# MCU_CTRL_MMR0_CFG0 register map
Vendor: Texas Instruments
Registers are 32-bit, read-write, reset 0x0 unless marked. A register's access mark holds for its fields unless they carry their own. Offsets are as the file gives them; [hi:lo] are bit positions; {n}, {i} and the like mark numbered series.

## MCU_CTRL_MMR0_CFG0 (part 2 of 2)
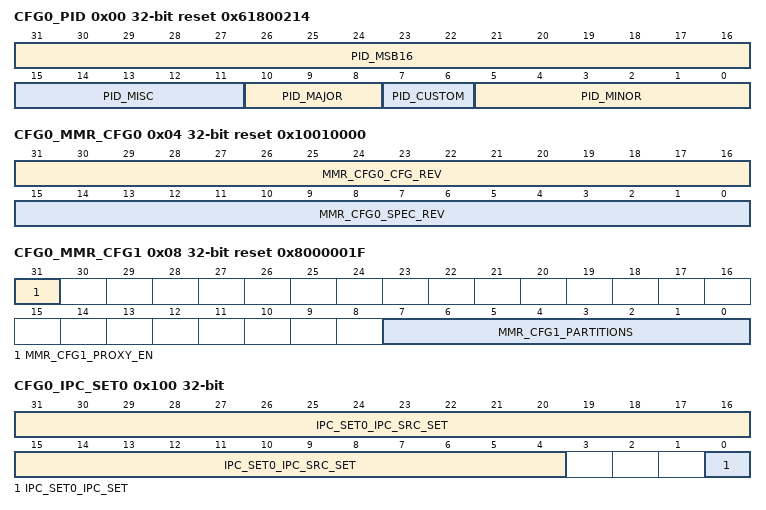
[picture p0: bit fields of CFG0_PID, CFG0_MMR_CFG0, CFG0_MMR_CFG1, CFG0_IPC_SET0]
0x00 CFG0_PID ro reset 0x61800214
  [31:16] PID_MSB16, [15:11] PID_MISC, [10:8] PID_MAJOR, [7:6] PID_CUSTOM, [5:0] PID_MINOR
0x04 CFG0_MMR_CFG0 ro reset 0x10010000
  [31:16] MMR_CFG0_CFG_REV — Major configuration release
  [15:0] MMR_CFG0_SPEC_REV — Minor spec-only revision. Doesn't change with RTL release so RTL will always read as 16'h0000
0x08 CFG0_MMR_CFG1 ro reset 0x8000001F
  [31] MMR_CFG1_PROXY_EN — Proxy addressing enabled
  [7:0] MMR_CFG1_PARTITIONS — Indicates present partitions
0x100 CFG0_IPC_SET0 access not given
  [31:4] IPC_SET0_IPC_SRC_SET — Read returns current value Write: 0 - No effect 1 - Sets both SRC_SETx and the SRC_CLRx bit in the corresponding IPC_CLR register (access R/W1TS)
  [0] IPC_SET0_IPC_SET — Read returns 0 Write: 0 - No effect 1 - Sets both the IPC_SET and the IPC_CLR bit in the corresponding IPC_CLR register (access R/W1TS)
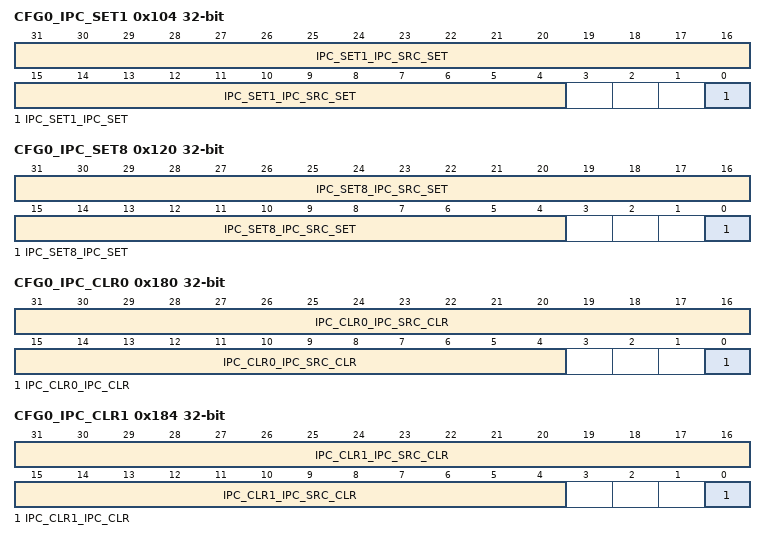
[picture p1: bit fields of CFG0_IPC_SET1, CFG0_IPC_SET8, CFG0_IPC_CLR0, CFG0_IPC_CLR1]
0x104 CFG0_IPC_SET1 access not given
  [31:4] IPC_SET1_IPC_SRC_SET — Read returns current value Write: 0 - No effect 1 - Sets both SRC_SETx and the SRC_CLRx bit in the corresponding IPC_CLR register (access R/W1TS)
  [0] IPC_SET1_IPC_SET — Read returns 0 Write: 0 - No effect 1 - Sets both the IPC_SET and the IPC_CLR bit in the corresponding IPC_CLR register (access R/W1TS)
0x120 CFG0_IPC_SET8 access not given
  [31:4] IPC_SET8_IPC_SRC_SET — Read returns current value Write: 0 - No effect 1 - Sets both SRC_SETx and the SRC_CLRx bit in the corresponding IPC_CLR register (access R/W1TS)
  [0] IPC_SET8_IPC_SET — Read returns 0 Write: 0 - No effect 1 - Sets both the IPC_SET and the IPC_CLR bit in the corresponding IPC_CLR register (access R/W1TS)
0x180 CFG0_IPC_CLR0 access not given
  [31:4] IPC_CLR0_IPC_SRC_CLR — Read returns current value Write: 0 - No effect 1 - Clears both SRC_CLRx and the SRC_SETx bit in the corresponding IPC_GEN register (access R/W1TC)
  [0] IPC_CLR0_IPC_CLR — Read returns current value Write: 0 - No effect 1 - Clears both IPC_CLR and the IPC_SET bit in the corresponding IPC_SET register (access R/W1TC)
0x184 CFG0_IPC_CLR1 access not given
  [31:4] IPC_CLR1_IPC_SRC_CLR — Read returns current value Write: 0 - No effect 1 - Clears both SRC_CLRx and the SRC_SETx bit in the corresponding IPC_GEN register (access R/W1TC)
  [0] IPC_CLR1_IPC_CLR — Read returns current value Write: 0 - No effect 1 - Clears both IPC_CLR and the IPC_SET bit in the corresponding IPC_SET register (access R/W1TC)
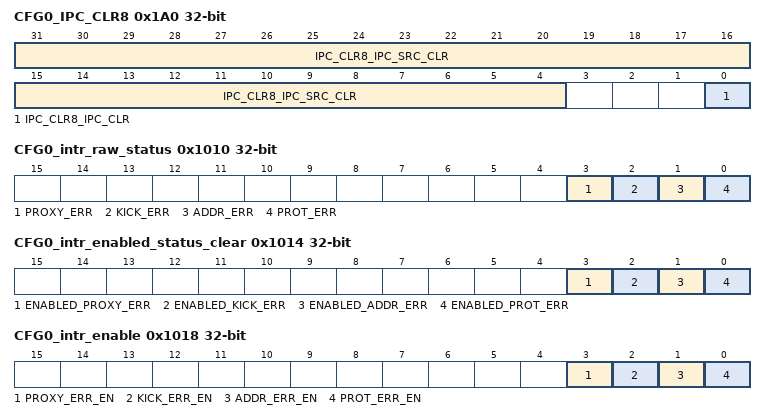
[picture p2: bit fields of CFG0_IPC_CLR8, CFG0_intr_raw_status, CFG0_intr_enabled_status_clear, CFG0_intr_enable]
0x1A0 CFG0_IPC_CLR8 access not given
  [31:4] IPC_CLR8_IPC_SRC_CLR — Read returns current value Write: 0 - No effect 1 - Clears both SRC_CLRx and the SRC_SETx bit in the corresponding IPC_GEN register (access R/W1TC)
  [0] IPC_CLR8_IPC_CLR — Read returns current value Write: 0 - No effect 1 - Clears both IPC_CLR and the IPC_SET bit in the corresponding IPC_SET register (access R/W1TC)
0x200 CFG0_MAC_ID0
  [31:0] MAC_ID0_MACID_LO — 32 lsbs of MAC address This bitfield may be written only once after each module reset .
0x204 CFG0_MAC_ID1
  [15:0] MAC_ID1_MACID_HI — 16 msbs of MAC address This bitfield may be written only once after each module reset .
0x208 CFG0_MAC_ID_COUNT ro
  [3:0] MAC_ID_COUNT_COUNT — Indicates the number of MAC addresses to be assigned
{0x1008+0x4000*i} CFG0_LOCK{i}_KICK0 (i=0..4)
  [31:0] LOCK{i}_KICK0 — - KICK0 component
{0x100C+0x4000*i} CFG0_LOCK{i}_KICK1 (i=0..4)
  [31:0] LOCK{i}_KICK1 — - KICK1 component
0x1010 CFG0_intr_raw_status access not given
  [3] PROXY_ERR — Proxy0 access violation error. Raw status is read. Write a 1 to set the status. Writing a 0 has no effect. (access R/W1TS)
  [2] KICK_ERR — Kick access violation error. Raw status is read. Write a 1 to set the status. Writing a 0 has no effect. (access R/W1TS)
  [1] ADDR_ERR — Addressing violation error. Raw status is read. Write a 1 to set the status. Writing a 0 has no effect. (access R/W1TS)
  [0] PROT_ERR — Protection violation error. Raw status is read. Write a 1 to set the status. Writing a 0 has no effect. (access R/W1TS)
0x1014 CFG0_intr_enabled_status_clear access not given
  [3] ENABLED_PROXY_ERR — Proxy0 access violation error. Enabled status is read. Write a 1 to clear the status. Writing a 0 has no effect. (access R/W1TC)
  [2] ENABLED_KICK_ERR — Kick access violation error. Enabled status is read. Write a 1 to clear the status. Writing a 0 has no effect. (access R/W1TC)
  [1] ENABLED_ADDR_ERR — Addressing violation error. Enabled status is read. Write a 1 to clear the status. Writing a 0 has no effect. (access R/W1TC)
  [0] ENABLED_PROT_ERR — Protection violation error. Enabled status is read. Write a 1 to clear the status. Writing a 0 has no effect. (access R/W1TC)
0x1018 CFG0_intr_enable access not given
  [3] PROXY_ERR_EN — Proxy0 access violation error enable. Write a 1 to set the enable. Writing a 0 has no effect. (access R/W1TS)
  [2] KICK_ERR_EN — Kick access violation error enable. Write a 1 to set the enable. Writing a 0 has no effect. (access R/W1TS)
  [1] ADDR_ERR_EN — Addressing violation error enable. Write a 1 to set the enable. Writing a 0 has no effect. (access R/W1TS)
  [0] PROT_ERR_EN — Protection violation error enable. Write a 1 to set the enable. Writing a 0 has no effect. (access R/W1TS)
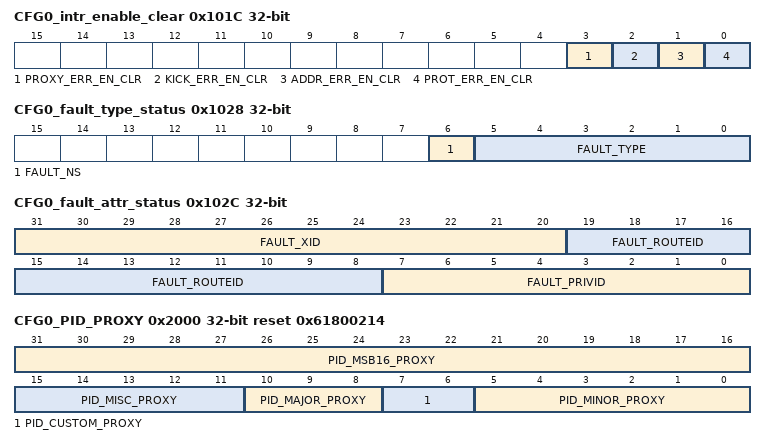
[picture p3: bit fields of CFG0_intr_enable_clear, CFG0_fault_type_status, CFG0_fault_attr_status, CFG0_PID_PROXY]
0x101C CFG0_intr_enable_clear access not given
  [3] PROXY_ERR_EN_CLR — Proxy0 access violation error enable clear. Write a 1 to clear the enable. Writing a 0 has no effect. (access R/W1TC)
  [2] KICK_ERR_EN_CLR — Kick access violation error enable clear. Write a 1 to clear the enable. Writing a 0 has no effect. (access R/W1TC)
  [1] ADDR_ERR_EN_CLR — Addressing violation error enable clear. Write a 1 to clear the enable. Writing a 0 has no effect. (access R/W1TC)
  [0] PROT_ERR_EN_CLR — Protection violation error enable clear. Write a 1 to clear the enable. Writing a 0 has no effect. (access R/W1TC)
0x1020 CFG0_eoi
  [7:0] EOI_VECTOR — EOI vector value. Write this with interrupt distribution value in the chip.
0x1024 CFG0_fault_address ro
  [31:0] FAULT_ADDR — Fault Address.
0x1028 CFG0_fault_type_status ro
  [6] FAULT_NS — Non-secure access.
  [5:0] FAULT_TYPE — Fault Type 10_0000 = Supervisor read fault - priv = 1 dir = 1 dtype != 1 01_0000 = Supervisor write fault - priv = 1 dir = 0 00_1000 = Supervisor execute fault - priv = 1 dir = 1 dtype = 1 00_0100 = User read fault - priv = 0 dir = 1 dtype = 1 00_0010 = User write fault - priv = 0 dir = 0 00_0001 = User execute fault - priv = 0 dir = 1 dtype = 1 00_0000 = No fault
0x102C CFG0_fault_attr_status ro
  [31:20] FAULT_XID — XID.
  [19:8] FAULT_ROUTEID — Route ID.
  [7:0] FAULT_PRIVID — Privilege ID.
0x1030 CFG0_fault_clear wo
  [0] FAULT_CLR — Fault clear. Writing a 1 clears the current fault. Writing a 0 has no effect.
{0x1100+4i} CFG0_CLAIMREG_P0_R{i}_READONLY ro (i=0..4)
  [31:0] CLAIMREG_P0_R{i}_READONLY — Claim bits for Partition 0
0x2000 CFG0_PID_PROXY ro reset 0x61800214
  [31:16] PID_MSB16_PROXY, [15:11] PID_MISC_PROXY, [10:8] PID_MAJOR_PROXY, [7:6] PID_CUSTOM_PROXY, [5:0] PID_MINOR_PROXY
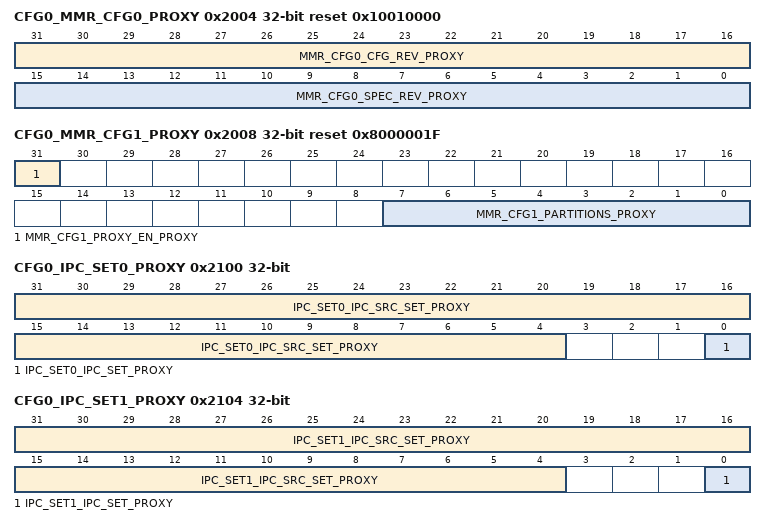
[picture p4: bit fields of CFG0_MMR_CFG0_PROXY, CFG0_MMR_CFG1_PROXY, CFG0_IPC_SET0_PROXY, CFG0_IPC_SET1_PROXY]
0x2004 CFG0_MMR_CFG0_PROXY ro reset 0x10010000
  [31:16] MMR_CFG0_CFG_REV_PROXY — Major configuration release
  [15:0] MMR_CFG0_SPEC_REV_PROXY — Minor spec-only revision. Doesn't change with RTL release so RTL will always read as 16'h0000
0x2008 CFG0_MMR_CFG1_PROXY ro reset 0x8000001F
  [31] MMR_CFG1_PROXY_EN_PROXY — Proxy addressing enabled
  [7:0] MMR_CFG1_PARTITIONS_PROXY — Indicates present partitions
0x2100 CFG0_IPC_SET0_PROXY access not given
  [31:4] IPC_SET0_IPC_SRC_SET_PROXY — Read returns current value Write: 0 - No effect 1 - Sets both SRC_SETx and the SRC_CLRx bit in the corresponding IPC_CLR register (access R/W1TS)
  [0] IPC_SET0_IPC_SET_PROXY — Read returns 0 Write: 0 - No effect 1 - Sets both the IPC_SET and the IPC_CLR bit in the corresponding IPC_CLR register (access R/W1TS)
0x2104 CFG0_IPC_SET1_PROXY access not given
  [31:4] IPC_SET1_IPC_SRC_SET_PROXY — Read returns current value Write: 0 - No effect 1 - Sets both SRC_SETx and the SRC_CLRx bit in the corresponding IPC_CLR register (access R/W1TS)
  [0] IPC_SET1_IPC_SET_PROXY — Read returns 0 Write: 0 - No effect 1 - Sets both the IPC_SET and the IPC_CLR bit in the corresponding IPC_CLR register (access R/W1TS)
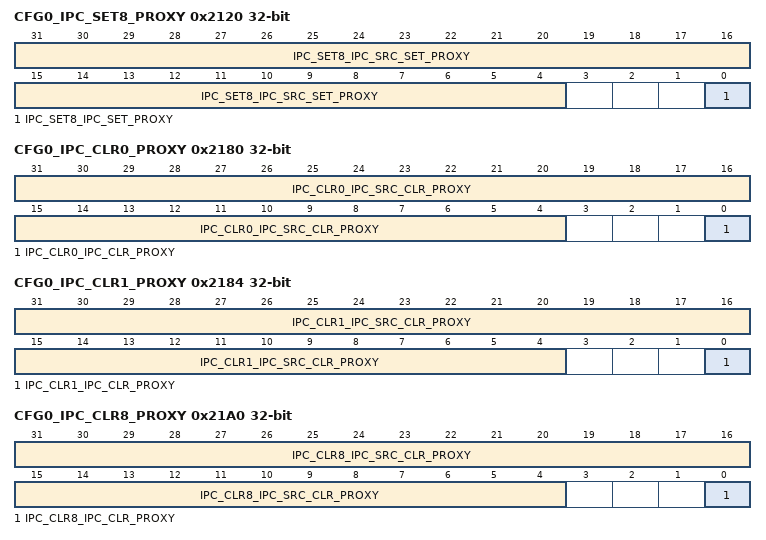
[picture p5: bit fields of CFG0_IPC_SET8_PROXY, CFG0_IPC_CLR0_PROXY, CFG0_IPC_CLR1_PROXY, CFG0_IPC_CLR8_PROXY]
0x2120 CFG0_IPC_SET8_PROXY access not given
  [31:4] IPC_SET8_IPC_SRC_SET_PROXY — Read returns current value Write: 0 - No effect 1 - Sets both SRC_SETx and the SRC_CLRx bit in the corresponding IPC_CLR register (access R/W1TS)
  [0] IPC_SET8_IPC_SET_PROXY — Read returns 0 Write: 0 - No effect 1 - Sets both the IPC_SET and the IPC_CLR bit in the corresponding IPC_CLR register (access R/W1TS)
0x2180 CFG0_IPC_CLR0_PROXY access not given
  [31:4] IPC_CLR0_IPC_SRC_CLR_PROXY — Read returns current value Write: 0 - No effect 1 - Clears both SRC_CLRx and the SRC_SETx bit in the corresponding IPC_GEN register (access R/W1TC)
  [0] IPC_CLR0_IPC_CLR_PROXY — Read returns current value Write: 0 - No effect 1 - Clears both IPC_CLR and the IPC_SET bit in the corresponding IPC_SET register (access R/W1TC)
0x2184 CFG0_IPC_CLR1_PROXY access not given
  [31:4] IPC_CLR1_IPC_SRC_CLR_PROXY — Read returns current value Write: 0 - No effect 1 - Clears both SRC_CLRx and the SRC_SETx bit in the corresponding IPC_GEN register (access R/W1TC)
  [0] IPC_CLR1_IPC_CLR_PROXY — Read returns current value Write: 0 - No effect 1 - Clears both IPC_CLR and the IPC_SET bit in the corresponding IPC_SET register (access R/W1TC)
0x21A0 CFG0_IPC_CLR8_PROXY access not given
  [31:4] IPC_CLR8_IPC_SRC_CLR_PROXY — Read returns current value Write: 0 - No effect 1 - Clears both SRC_CLRx and the SRC_SETx bit in the corresponding IPC_GEN register (access R/W1TC)
  [0] IPC_CLR8_IPC_CLR_PROXY — Read returns current value Write: 0 - No effect 1 - Clears both IPC_CLR and the IPC_SET bit in the corresponding IPC_SET register (access R/W1TC)
0x2200 CFG0_MAC_ID0_PROXY
  [31:0] MAC_ID0_MACID_LO_PROXY — 32 lsbs of MAC address This bitfield may be written only once after each module reset .
0x2204 CFG0_MAC_ID1_PROXY
  [15:0] MAC_ID1_MACID_HI_PROXY — 16 msbs of MAC address This bitfield may be written only once after each module reset .
0x2208 CFG0_MAC_ID_COUNT_PROXY ro
  [3:0] MAC_ID_COUNT_COUNT_PROXY — Indicates the number of MAC addresses to be assigned
{0x3008+0x4000*i} CFG0_LOCK{i}_KICK0_PROXY (i=0..4)
  [31:0] LOCK{i}_KICK0_PROXY — - KICK0 component
{0x300C+0x4000*i} CFG0_LOCK{i}_KICK1_PROXY (i=0..4)
  [31:0] LOCK{i}_KICK1_PROXY — - KICK1 component
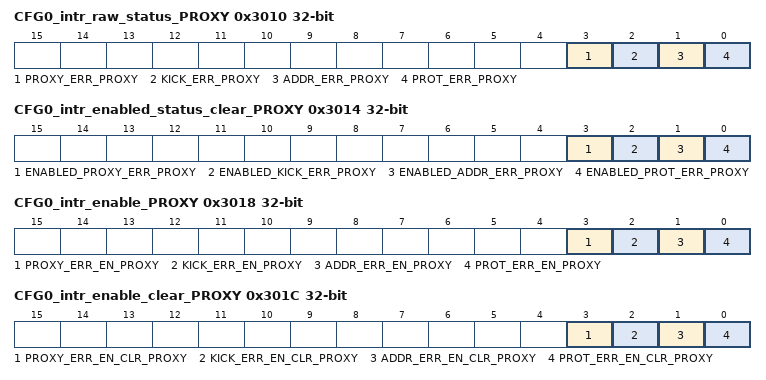
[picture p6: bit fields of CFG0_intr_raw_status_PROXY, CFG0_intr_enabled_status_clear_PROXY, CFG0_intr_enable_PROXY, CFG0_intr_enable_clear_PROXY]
0x3010 CFG0_intr_raw_status_PROXY access not given
  [3] PROXY_ERR_PROXY — Proxy0 access violation error. Raw status is read. Write a 1 to set the status. Writing a 0 has no effect. (access R/W1TS)
  [2] KICK_ERR_PROXY — Kick access violation error. Raw status is read. Write a 1 to set the status. Writing a 0 has no effect. (access R/W1TS)
  [1] ADDR_ERR_PROXY — Addressing violation error. Raw status is read. Write a 1 to set the status. Writing a 0 has no effect. (access R/W1TS)
  [0] PROT_ERR_PROXY — Protection violation error. Raw status is read. Write a 1 to set the status. Writing a 0 has no effect. (access R/W1TS)
0x3014 CFG0_intr_enabled_status_clear_PROXY access not given
  [3] ENABLED_PROXY_ERR_PROXY — Proxy0 access violation error. Enabled status is read. Write a 1 to clear the status. Writing a 0 has no effect. (access R/W1TC)
  [2] ENABLED_KICK_ERR_PROXY — Kick access violation error. Enabled status is read. Write a 1 to clear the status. Writing a 0 has no effect. (access R/W1TC)
  [1] ENABLED_ADDR_ERR_PROXY — Addressing violation error. Enabled status is read. Write a 1 to clear the status. Writing a 0 has no effect. (access R/W1TC)
  [0] ENABLED_PROT_ERR_PROXY — Protection violation error. Enabled status is read. Write a 1 to clear the status. Writing a 0 has no effect. (access R/W1TC)
0x3018 CFG0_intr_enable_PROXY access not given
  [3] PROXY_ERR_EN_PROXY — Proxy0 access violation error enable. Write a 1 to set the enable. Writing a 0 has no effect. (access R/W1TS)
  [2] KICK_ERR_EN_PROXY — Kick access violation error enable. Write a 1 to set the enable. Writing a 0 has no effect. (access R/W1TS)
  [1] ADDR_ERR_EN_PROXY — Addressing violation error enable. Write a 1 to set the enable. Writing a 0 has no effect. (access R/W1TS)
  [0] PROT_ERR_EN_PROXY — Protection violation error enable. Write a 1 to set the enable. Writing a 0 has no effect. (access R/W1TS)
0x301C CFG0_intr_enable_clear_PROXY access not given
  [3] PROXY_ERR_EN_CLR_PROXY — Proxy0 access violation error enable clear. Write a 1 to clear the enable. Writing a 0 has no effect. (access R/W1TC)
  [2] KICK_ERR_EN_CLR_PROXY — Kick access violation error enable clear. Write a 1 to clear the enable. Writing a 0 has no effect. (access R/W1TC)
  [1] ADDR_ERR_EN_CLR_PROXY — Addressing violation error enable clear. Write a 1 to clear the enable. Writing a 0 has no effect. (access R/W1TC)
  [0] PROT_ERR_EN_CLR_PROXY — Protection violation error enable clear. Write a 1 to clear the enable. Writing a 0 has no effect. (access R/W1TC)
0x3020 CFG0_eoi_PROXY
  [7:0] EOI_VECTOR_PROXY — EOI vector value. Write this with interrupt distribution value in the chip.
0x3024 CFG0_fault_address_PROXY ro
  [31:0] FAULT_ADDR_PROXY — Fault Address.
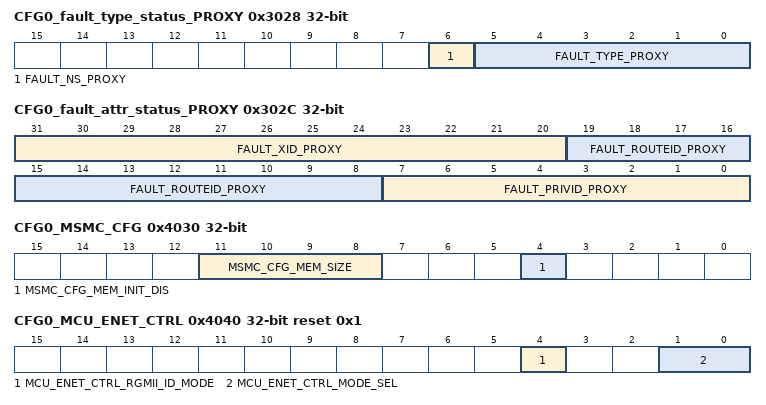
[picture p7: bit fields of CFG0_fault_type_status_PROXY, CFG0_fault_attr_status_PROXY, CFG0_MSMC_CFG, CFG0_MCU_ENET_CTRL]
0x3028 CFG0_fault_type_status_PROXY ro
  [6] FAULT_NS_PROXY — Non-secure access.
  [5:0] FAULT_TYPE_PROXY — Fault Type 10_0000 = Supervisor read fault - priv = 1 dir = 1 dtype != 1 01_0000 = Supervisor write fault - priv = 1 dir = 0 00_1000 = Supervisor execute fault - priv = 1 dir = 1 dtype = 1 00_0100 = User read fault - priv = 0 dir = 1 dtype = 1 00_0010 = User write fault - priv = 0 dir = 0 00_0001 = User execute fault - priv = 0 dir = 1 dtype = 1 00_0000 = No fault
0x302C CFG0_fault_attr_status_PROXY ro
  [31:20] FAULT_XID_PROXY — XID.
  [19:8] FAULT_ROUTEID_PROXY — Route ID.
  [7:0] FAULT_PRIVID_PROXY — Privilege ID.
0x3030 CFG0_fault_clear_PROXY wo
  [0] FAULT_CLR_PROXY — Fault clear. Writing a 1 clears the current fault. Writing a 0 has no effect.
{0x3100+4i} CFG0_CLAIMREG_P0_R{i} (i=0..4)
  [31:0] CLAIMREG_P0_R{i} — Claim bits for Partition 0
0x4030 CFG0_MSMC_CFG access per field
  [11:8] MSMC_CFG_MEM_SIZE ro — Indicates the size of MSMC shared SRAM/Cache Field values (others are reserved): undefined - undefined undefined - undefined undefined - undefined undefined - undefined undefined - undefined undefined - undefined undefined - undefined undefined - undefined undefined - undefined undefined - undefined undefined - undefined undefined - undefined undefined - undefined undefined - undefined 4'b0000 - 0.5 MB 4'b0001 - 1.75 MB 4'b0010 - 3.0 MB 4'b0011 - 4,25 MB 4'b0100 - 5.5 MB 4'b0101 - 6.75 MB 4'b0110 - 8 MB 4'b0111 - 9.25 MB 4'b1000 - 10.5 MB 4'b1001 - 11.75 MB 4'b1010 - 13.0 MB
  [4] MSMC_CFG_MEM_INIT_DIS rw — Disables MSMC SRAM initialization (Data, Cache Tags, and Snoop Filters). This is required for proper initial ECC initialization. 1'b0 - Perform memory initialization 1'b1 - Disable memory initialization
0x4040 CFG0_MCU_ENET_CTRL reset 0x1
  [4] MCU_ENET_CTRL_RGMII_ID_MODE — Port1 RGMII internal transmit delay selection 0 - Internal transmit delay 1 - No internal transmit delay
  [1:0] MCU_ENET_CTRL_MODE_SEL — Selects Ethernet switch Port1 interface Field values (others are reserved): 2'b00 - GMII/MII (not supported) 2'b01 - RMII 2'b10 - RGMII 2'b11 - SGMII (not supported)
0x4060 CFG0_MCU_SPI1_CTRL
  [0] MCU_SPI1_CTRL_SPI1_LINKDIS — Disables direct connection of MCU_SPI1 to SPI3 Field values (others are reserved): 1'b0 - MCU_SPI1 is tied as a slave to SPI3. MCU_SPI1 CLK, DATA1 and CS0 are driven from SPI3, DATA OUT drives SPI3 DATA0 1'b1 - MCU_SPI1 is NOT tied as a slave to SPI3. MCU_SPI1 CLK, DATA0, DATA1 and CS[3:0] are controlled through their respective MCU_SPI1 pins and SPI3 CLK, DATA0, DATA1, and CS[3:0] are controlled through their respective SPI3 pins.
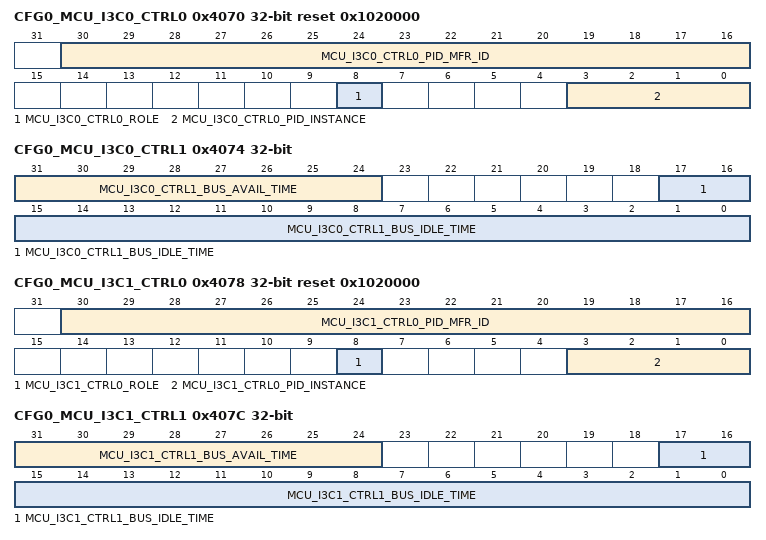
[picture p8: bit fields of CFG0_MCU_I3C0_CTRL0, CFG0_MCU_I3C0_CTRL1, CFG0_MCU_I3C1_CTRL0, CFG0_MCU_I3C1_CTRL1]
0x4070 CFG0_MCU_I3C0_CTRL0 reset 0x1020000
  [30:16] MCU_I3C0_CTRL0_PID_MFR_ID — Manufacturer ID This input corresponds to bits[47:33] of the Provisional ID to identify the manufacturer. Defaults to TI value.
  [8] MCU_I3C0_CTRL0_ROLE — Master Role 0 - Main master 1 - Secondary master
  [3:0] MCU_I3C0_CTRL0_PID_INSTANCE — Provisional ID Instance. This input corresponds to bits[15:12] of the Provisional ID. It is intended to provide a way of differentiating several I3C devices if there would be no other way to have each manufactured device have a unique Provisional ID
0x4074 CFG0_MCU_I3C0_CTRL1
  [31:24] MCU_I3C0_CTRL1_BUS_AVAIL_TIME — Indicates the number of pclk cycles in the Bus Available condition
  [17:0] MCU_I3C0_CTRL1_BUS_IDLE_TIME — Indicates the number of pclk cycles in the Bus Idle condition
0x4078 CFG0_MCU_I3C1_CTRL0 reset 0x1020000
  [30:16] MCU_I3C1_CTRL0_PID_MFR_ID — Manufacturer ID This input corresponds to bits[47:33] of the Provisional ID to identify the manufacturer. Defaults to TI value.
  [8] MCU_I3C1_CTRL0_ROLE — Master Role 0 - Main master 1 - Secondary master
  [3:0] MCU_I3C1_CTRL0_PID_INSTANCE — Provisional ID Instance. This input corresponds to bits[15:12] of the Provisional ID. It is intended to provide a way of differentiating several I3C devices if there would be no other way to have each manufactured device have a unique Provisional ID
0x407C CFG0_MCU_I3C1_CTRL1
  [31:24] MCU_I3C1_CTRL1_BUS_AVAIL_TIME — Indicates the number of pclk cycles in the Bus Available condition
  [17:0] MCU_I3C1_CTRL1_BUS_IDLE_TIME — Indicates the number of pclk cycles in the Bus Idle condition
0x4080 CFG0_MCU_I2C0_CTRL
  [0] MCU_I2C0_CTRL_HS_MCS_EN — HS Mode master current source enable. When set, enables the current-source pull-up on the SCL output. Only one master on the I2C bus should enable SCL current sourcing.
0x4084 CFG0_MCU_I2C1_CTRL
  [0] MCU_I2C1_CTRL_HS_MCS_EN — HS Mode master current source enable. When set, enables the current-source pull-up on the SCL output. Only one master on the I2C bus should enable SCL current sourcing.
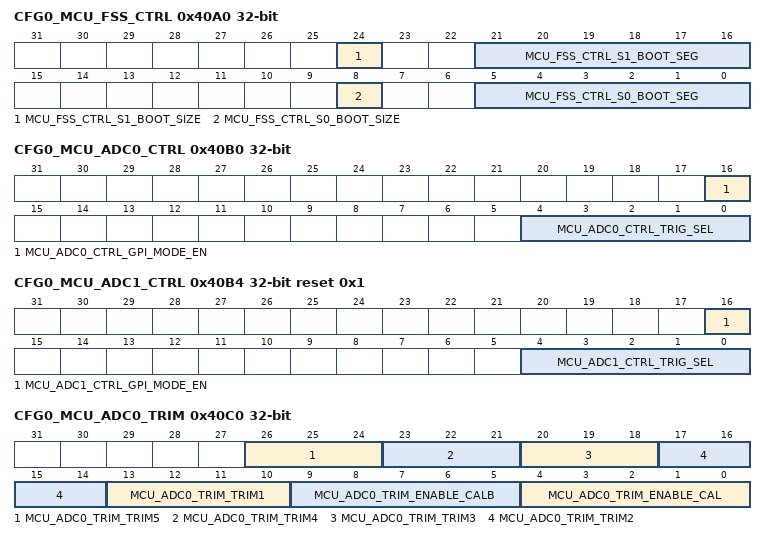
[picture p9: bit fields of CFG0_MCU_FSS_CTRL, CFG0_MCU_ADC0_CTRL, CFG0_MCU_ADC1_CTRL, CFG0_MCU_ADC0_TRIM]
0x40A0 CFG0_MCU_FSS_CTRL
  [24] MCU_FSS_CTRL_S1_BOOT_SIZE — Selects the size of the boot block to be used for the S1 (OSPI1) flash interface 0 - S1 boot size is 64 MB 1 - S1 boot size is 128 MB
  [21:16] MCU_FSS_CTRL_S1_BOOT_SEG — Selects the boot block to be used for the S1 (OSPI1) flash interface. If the s1_boot_size is 128 MB then only bits [4:0] of this field are used. Care must be taken to account for the address translation as to not fall off or wrap the address of the flash. (e.g. if both ECC and authentication are enabled for 64 MB boot, the highest valid block number is 49, as sector 50 is only .2M Bytes in size.) 6'h00 - Use block 0 6'h01 - Use block 1 : 6'h3F - Use block 63
  [8] MCU_FSS_CTRL_S0_BOOT_SIZE — Selects the size of the boot block to be used for the S0 (OSPI0 or Hyperbus) flash interface 0 - S0 boot size is 64 MB 1 - S0 boot size is 128 MB
  [5:0] MCU_FSS_CTRL_S0_BOOT_SEG — Selects the boot block to be used for the S0 (OSPI0 or Hyperbus) flash interface. If the s0_boot_size is 128 MB then only bits [4:0] of this field are used. Care must be taken to account for the address translation as to not fall off or wrap the address of the flash. (e.g. if both ECC and authentication are enabled for 64 MB boot, the highest valid block number is 49, as sector 50 is only .2M Bytes in size.) 6'h00 - Use block 0 6'h01 - Use block 1 : 6'h3F - Use block 63
0x40B0 CFG0_MCU_ADC0_CTRL
  [16] MCU_ADC0_CTRL_GPI_MODE_EN — Enables MCU_ADC0 data pins to be used as general purpose inputs when set. This signal is tied to the en_dig_test input of MCU_ADC0
  [4:0] MCU_ADC0_CTRL_TRIG_SEL — Selects the source of the ADC hardware event trigger Field values (others are reserved): 5'b00000 - MCU_ADC_EXT_TRIGGER0 pin 5'b00001 - MCU_ADC_EXT_TRIGGER1 pin 5'b00010 - eHRPWM SOCA event 5'b00011 - eHRPWM SOCB event 5'b00100 - MCU Timer0 PWM output 5'b00101 - MCU Timer1 PWM output 5'b00110 - MCU Timer2 PWM output 5'b00111 - MCU Timer3 PWM output 5'b01000 - Timer0 PWM output 5'b01001 - Timer1 PWM output 5'b01010 - Timer2 PWM output 5'b01011 - Timer3 PWM output 5'b01100 - Timer4 PWM output 5'b01101 - Timer5 PWM output 5'b01110 - Timer6 PWM output 5'b01111 - Timer7 PWM output 5'b10000 - Timer8 PWM output 5'b10001 - Timer9 PWM output 5'b10010 - Timer10 PWM output 5'b10011 - Timer11 PWM output undefined - undefined 5'b10101 - Reserved (tied 1'b0) undefined - undefined 5'b10110 - Reserved (tied 1'b0) undefined - undefined 5'b10111 - Reserved (tied 1'b0) undefined - undefined 5'b11000 - Reserved (tied 1'b0) 5'b11000 - MCU Timer4 PWM output 5'b11001 - MCU Timer5 PWM output 5'b11010 - MCU Timer6 PWM output 5'b11011 - MCU Timer7 PWM output 5'b11100 - MCU Timer8 PWM output 5'b11101 - MCU Timer9 PWM output 5'b11110 - Reserved (tied 1'b0) 5'b11111 - Reserved (tied 1'b0)
0x40B4 CFG0_MCU_ADC1_CTRL reset 0x1
  [16] MCU_ADC1_CTRL_GPI_MODE_EN — Enables MCU_ADC1 data pins to be used as general purpose inputs when set. This signal is tied to the en_dig_test input of MCU_ADC1
  [4:0] MCU_ADC1_CTRL_TRIG_SEL — Selects the source of the ADC hardware event trigger Field values (others are reserved): 5'b00000 - MCU_ADC_EXT_TRIGGER0 pin 5'b00001 - MCU_ADC_EXT_TRIGGER1 pin 5'b00010 - eHRPWM SOCA event 5'b00011 - eHRPWM SOCB event 5'b00100 - MCU Timer0 PWM output 5'b00101 - MCU Timer1 PWM output 5'b00110 - MCU Timer2 PWM output 5'b00111 - MCU Timer3 PWM output 5'b01000 - Timer0 PWM output 5'b01001 - Timer1 PWM output 5'b01010 - Timer2 PWM output 5'b01011 - Timer3 PWM output 5'b01100 - Timer4 PWM output 5'b01101 - Timer5 PWM output 5'b01110 - Timer6 PWM output 5'b01111 - Timer7 PWM output 5'b10000 - Timer8 PWM output 5'b10001 - Timer9 PWM output 5'b10010 - Timer10 PWM output 5'b10011 - Timer11 PWM output undefined - undefined 5'b10101 - Reserved (tied 1'b0) undefined - undefined 5'b10110 - Reserved (tied 1'b0) undefined - undefined undefined - undefined 5'b11000 - MCU Timer4 PWM output 5'b11001 - MCU Timer5 PWM output 5'b11010 - MCU Timer6 PWM output 5'b11011 - MCU Timer7 PWM output 5'b11100 - MCU Timer8 PWM output 5'b11101 - MCU Timer9 PWM output 5'b11110 - Reserved (tied 1'b0) 5'b11111 - Reserved (tied 1'b0)
0x40C0 CFG0_MCU_ADC0_TRIM
  [26:24] MCU_ADC0_TRIM_TRIM5 — Trim value for C5 0.37 fF to 3.2fF in ~0.37fF increments
  [23:21] MCU_ADC0_TRIM_TRIM4 — Trim value for C4 0.37 fF to 3.2fF in ~0.37fF increments
  [20:18] MCU_ADC0_TRIM_TRIM3 — Trim value for C3 0.37 fF to 3.2fF in ~0.37fF increments
  [17:14] MCU_ADC0_TRIM_TRIM2 — Trim value for C2 0.37 fF to 6.4fF in ~0.37fF increments
  [13:10] MCU_ADC0_TRIM_TRIM1 — Trim value for C1 0.37 fF to 6.4fF in ~0.37fF increments
  [9:5] MCU_ADC0_TRIM_ENABLE_CALB — Reserved. This bitfield no longer used
  [4:0] MCU_ADC0_TRIM_ENABLE_CAL — Reserved. This bitfield no longer used
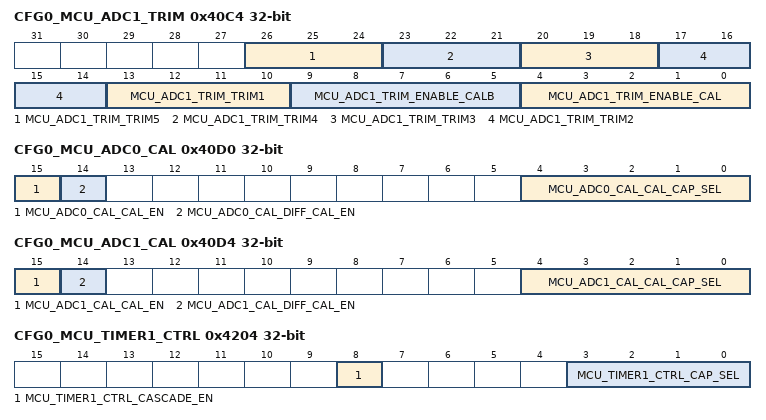
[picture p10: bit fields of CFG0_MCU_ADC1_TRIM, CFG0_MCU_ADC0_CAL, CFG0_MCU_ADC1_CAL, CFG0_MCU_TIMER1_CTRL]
0x40C4 CFG0_MCU_ADC1_TRIM
  [26:24] MCU_ADC1_TRIM_TRIM5 — Trim value for C5 0.37 fF to 3.2fF in ~0.37fF increments
  [23:21] MCU_ADC1_TRIM_TRIM4 — Trim value for C4 0.37 fF to 3.2fF in ~0.37fF increments
  [20:18] MCU_ADC1_TRIM_TRIM3 — Trim value for C3 0.37 fF to 3.2fF in ~0.37fF increments
  [17:14] MCU_ADC1_TRIM_TRIM2 — Trim value for C2 0.37 fF to 6.4fF in ~0.37fF increments
  [13:10] MCU_ADC1_TRIM_TRIM1 — Trim value for C1 0.37 fF to 6.4fF in ~0.37fF increments
  [9:5] MCU_ADC1_TRIM_ENABLE_CALB — Reserved. This bitfield no longer used
  [4:0] MCU_ADC1_TRIM_ENABLE_CAL — Reserved. This bitfield no longer used
0x40D0 CFG0_MCU_ADC0_CAL
  [15] MCU_ADC0_CAL_CAL_EN — Enable single-ended calibration Set to 1 to begin single-ended calibration
  [14] MCU_ADC0_CAL_DIFF_CAL_EN — Enable differential calibration Set to 1 to begin differential calibration
  [4:0] MCU_ADC0_CAL_CAL_CAP_SEL — Select capacitor for calibration Bits correspond to C5:C1 Field values (others are reserved): 5'b00000 - None 5'b00001 - Select C1 5'b00010 - Select C2 5'b00100 - Select C3 5'b01000 - Select C4 5'b10000 - Select C5
0x40D4 CFG0_MCU_ADC1_CAL
  [15] MCU_ADC1_CAL_CAL_EN — Enable single-ended calibration Set to 1 to begin single-ended calibration
  [14] MCU_ADC1_CAL_DIFF_CAL_EN — Enable differential calibration Set to 1 to begin differential calibration
  [4:0] MCU_ADC1_CAL_CAL_CAP_SEL — Select capacitor for calibration Bits correspond to C5:C1 Field values (others are reserved): 5'b00000 - None 5'b00001 - Select C1 5'b00010 - Select C2 5'b00100 - Select C3 5'b01000 - Select C4 5'b10000 - Select C5
0x4200 CFG0_MCU_TIMER0_CTRL
  [3:0] MCU_TIMER0_CTRL_CAP_SEL — Selects the MCU_TIMERIO input pin for capture input signal. This control is only used when TIMER0 is configured for capture operation. Field values (others are reserved): 4'b0000 - Use MCU_TIMER_IO0 pin 4'b0001 - Use MCU_TIMER_IO1 pin 4'b0010 - Use MCU_TIMER_IO2 pin 4'b0011 - Use MCU_TIMER_IO3 pin 4'b0100 - Use MCU_TIMER_IO4 pin 4'b0101 - Use MCU_TIMER_IO5 pin 4'b0110 - Use MCU_TIMER_IO6 pin 4'b0111 - Use MCU_TIMER_IO7 pin 4'b1000 - Use MCU_TIMER_IO8 pin 4'b1001 - Use MCU_TIMER_IO9 pin
0x4204 CFG0_MCU_TIMER1_CTRL
  [8] MCU_TIMER1_CTRL_CASCADE_EN — When set, enables cascading of MCU_TIMER1 to MCU_TIMER0
  [3:0] MCU_TIMER1_CTRL_CAP_SEL — Selects the MCU_TIMERIO input pin for capture input signal. This control is only used when TIMER1 is configured for capture operation. Field values (others are reserved): 4'b0000 - Use MCU_TIMER_IO0 pin 4'b0001 - Use MCU_TIMER_IO1 pin 4'b0010 - Use MCU_TIMER_IO2 pin 4'b0011 - Use MCU_TIMER_IO3 pin 4'b0100 - Use MCU_TIMER_IO4 pin 4'b0101 - Use MCU_TIMER_IO5 pin 4'b0110 - Use MCU_TIMER_IO6 pin 4'b0111 - Use MCU_TIMER_IO7 pin 4'b1000 - Use MCU_TIMER_IO8 pin 4'b1001 - Use MCU_TIMER_IO9 pin
0x4208 CFG0_MCU_TIMER2_CTRL
  [3:0] MCU_TIMER2_CTRL_CAP_SEL — Selects the MCU_TIMERIO input pin for capture input signal. This control is only used when TIMER2 is configured for capture operation. Field values (others are reserved): 4'b0000 - Use MCU_TIMER_IO0 pin 4'b0001 - Use MCU_TIMER_IO1 pin 4'b0010 - Use MCU_TIMER_IO2 pin 4'b0011 - Use MCU_TIMER_IO3 pin 4'b0100 - Use MCU_TIMER_IO4 pin 4'b0101 - Use MCU_TIMER_IO5 pin 4'b0110 - Use MCU_TIMER_IO6 pin 4'b0111 - Use MCU_TIMER_IO7 pin 4'b1000 - Use MCU_TIMER_IO8 pin 4'b1001 - Use MCU_TIMER_IO9 pin
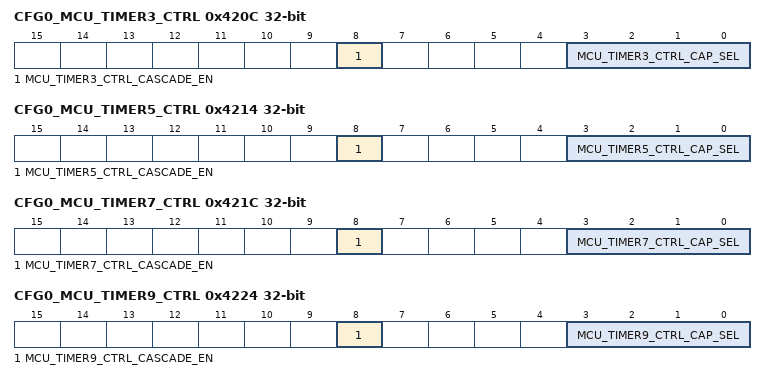
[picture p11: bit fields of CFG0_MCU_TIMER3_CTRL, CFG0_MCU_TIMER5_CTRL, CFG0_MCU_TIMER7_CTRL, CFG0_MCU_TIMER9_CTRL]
0x420C CFG0_MCU_TIMER3_CTRL
  [8] MCU_TIMER3_CTRL_CASCADE_EN — When set, enables cascading of MCU_TIMER3 to MCU_TIMER2
  [3:0] MCU_TIMER3_CTRL_CAP_SEL — Selects the MCU_TIMERIO input pin for capture input signal. This control is only used when TIMER3 is configured for capture operation. Field values (others are reserved): 4'b0000 - Use MCU_TIMER_IO0 pin 4'b0001 - Use MCU_TIMER_IO1 pin 4'b0010 - Use MCU_TIMER_IO2 pin 4'b0011 - Use MCU_TIMER_IO3 pin 4'b0100 - Use MCU_TIMER_IO4 pin 4'b0101 - Use MCU_TIMER_IO5 pin 4'b0110 - Use MCU_TIMER_IO6 pin 4'b0111 - Use MCU_TIMER_IO7 pin 4'b1000 - Use MCU_TIMER_IO8 pin 4'b1001 - Use MCU_TIMER_IO9 pin
0x4210 CFG0_MCU_TIMER4_CTRL
  [3:0] MCU_TIMER4_CTRL_CAP_SEL — Selects the MCU_TIMERIO input pin for capture input signal. This control is only used when TIMER4 is configured for capture operation. Field values (others are reserved): 4'b0000 - Use MCU_TIMER_IO0 pin 4'b0001 - Use MCU_TIMER_IO1 pin 4'b0010 - Use MCU_TIMER_IO2 pin 4'b0011 - Use MCU_TIMER_IO3 pin 4'b0100 - Use MCU_TIMER_IO4 pin 4'b0101 - Use MCU_TIMER_IO5 pin 4'b0110 - Use MCU_TIMER_IO6 pin 4'b0111 - Use MCU_TIMER_IO7 pin 4'b1000 - Use MCU_TIMER_IO8 pin 4'b1001 - Use MCU_TIMER_IO9 pin
0x4214 CFG0_MCU_TIMER5_CTRL
  [8] MCU_TIMER5_CTRL_CASCADE_EN — When set, enables cascading of MCU_TIMER5 to MCU_TIMER4
  [3:0] MCU_TIMER5_CTRL_CAP_SEL — Selects the MCU_TIMERIO input pin for capture input signal. This control is only used when TIMER5 is configured for capture operation. Field values (others are reserved): 4'b0000 - Use MCU_TIMER_IO0 pin 4'b0001 - Use MCU_TIMER_IO1 pin 4'b0010 - Use MCU_TIMER_IO2 pin 4'b0011 - Use MCU_TIMER_IO3 pin 4'b0100 - Use MCU_TIMER_IO4 pin 4'b0101 - Use MCU_TIMER_IO5 pin 4'b0110 - Use MCU_TIMER_IO6 pin 4'b0111 - Use MCU_TIMER_IO7 pin 4'b1000 - Use MCU_TIMER_IO8 pin 4'b1001 - Use MCU_TIMER_IO9 pin
0x4218 CFG0_MCU_TIMER6_CTRL
  [3:0] MCU_TIMER6_CTRL_CAP_SEL — Selects the MCU_TIMERIO input pin for capture input signal. This control is only used when TIMER6 is configured for capture operation. Field values (others are reserved): 4'b0000 - Use MCU_TIMER_IO0 pin 4'b0001 - Use MCU_TIMER_IO1 pin 4'b0010 - Use MCU_TIMER_IO2 pin 4'b0011 - Use MCU_TIMER_IO3 pin 4'b0100 - Use MCU_TIMER_IO4 pin 4'b0101 - Use MCU_TIMER_IO5 pin 4'b0110 - Use MCU_TIMER_IO6 pin 4'b0111 - Use MCU_TIMER_IO7 pin 4'b1000 - Use MCU_TIMER_IO8 pin 4'b1001 - Use MCU_TIMER_IO9 pin
0x421C CFG0_MCU_TIMER7_CTRL
  [8] MCU_TIMER7_CTRL_CASCADE_EN — When set, enables cascading of MCU_TIMER7 to MCU_TIMER6
  [3:0] MCU_TIMER7_CTRL_CAP_SEL — Selects the MCU_TIMERIO input pin for capture input signal. This control is only used when TIMER7 is configured for capture operation. Field values (others are reserved): 4'b0000 - Use MCU_TIMER_IO0 pin 4'b0001 - Use MCU_TIMER_IO1 pin 4'b0010 - Use MCU_TIMER_IO2 pin 4'b0011 - Use MCU_TIMER_IO3 pin 4'b0100 - Use MCU_TIMER_IO4 pin 4'b0101 - Use MCU_TIMER_IO5 pin 4'b0110 - Use MCU_TIMER_IO6 pin 4'b0111 - Use MCU_TIMER_IO7 pin 4'b1000 - Use MCU_TIMER_IO8 pin 4'b1001 - Use MCU_TIMER_IO9 pin
0x4220 CFG0_MCU_TIMER8_CTRL
  [3:0] MCU_TIMER8_CTRL_CAP_SEL — Selects the MCU_TIMERIO input pin for capture input signal. This control is only used when TIMER8 is configured for capture operation. Field values (others are reserved): 4'b0000 - Use MCU_TIMER_IO0 pin 4'b0001 - Use MCU_TIMER_IO1 pin 4'b0010 - Use MCU_TIMER_IO2 pin 4'b0011 - Use MCU_TIMER_IO3 pin 4'b0100 - Use MCU_TIMER_IO4 pin 4'b0101 - Use MCU_TIMER_IO5 pin 4'b0110 - Use MCU_TIMER_IO6 pin 4'b0111 - Use MCU_TIMER_IO7 pin 4'b1000 - Use MCU_TIMER_IO8 pin 4'b1001 - Use MCU_TIMER_IO9 pin
0x4224 CFG0_MCU_TIMER9_CTRL
  [8] MCU_TIMER9_CTRL_CASCADE_EN — When set, enables cascading of MCU_TIMER9 to MCU_TIMER8
  [3:0] MCU_TIMER9_CTRL_CAP_SEL — Selects the MCU_TIMERIO input pin for capture input signal. This control is only used when TIMER9 is configured for capture operation. Field values (others are reserved): 4'b0000 - Use MCU_TIMER_IO0 pin 4'b0001 - Use MCU_TIMER_IO1 pin 4'b0010 - Use MCU_TIMER_IO2 pin 4'b0011 - Use MCU_TIMER_IO3 pin 4'b0100 - Use MCU_TIMER_IO4 pin 4'b0101 - Use MCU_TIMER_IO5 pin 4'b0110 - Use MCU_TIMER_IO6 pin 4'b0111 - Use MCU_TIMER_IO7 pin 4'b1000 - Use MCU_TIMER_IO8 pin 4'b1001 - Use MCU_TIMER_IO9 pin
{0x4280+4i} CFG0_MCU_TIMERIO{i}_CTRL reset 0xF (i=0..9)
  [3:0] MCU_TIMERIO{i}_CTRL_OUT_SEL — Selects the source of the MCU_TIMERIO{i} output Field values (others are reserved): 4'b0000 - MCU_TIMERIO{i} is driven by MCU_TIMER0 output 4'b0001 - MCU_TIMERIO{i} is driven by MCU_TIMER1 output 4'b0010 - MCU_TIMERIO{i} is driven by MCU_TIMER2 output 4'b0011 - MCU_TIMERIO{i} is driven by MCU_TIMER3 output 4'b0100 - MCU_TIMERIO{i} is driven by MCU_TIMER4 output 4'b0101 - MCU_TIMERIO{i} is driven by MCU_TIMER5 output 4'b0110 - MCU_TIMERIO{i} is driven by MCU_TIMER6 output 4'b0111 - MCU_TIMERIO{i} is driven by MCU_TIMER7 output 4'b1000 - MCU_TIMERIO{i} is driven by MCU_TIMER8 output 4'b1001 - MCU_TIMERIO{i} is driven by MCU_TIMER9 output 4'b1010 - MCU_TIMERIO{i} is driven low 4'b1011 - MCU_TIMERIO{i} is driven high 4'b1100 - MCU_TIMERIO{i} is driven low 4'b1101 - MCU_TIMERIO{i} is driven high 4'b1110 - MCU_TIMERIO{i} is driven low 4'b1111 - MCU_TIMERIO{i} is driven high
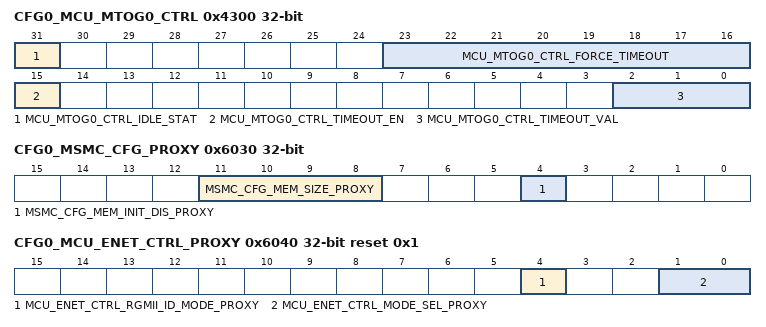
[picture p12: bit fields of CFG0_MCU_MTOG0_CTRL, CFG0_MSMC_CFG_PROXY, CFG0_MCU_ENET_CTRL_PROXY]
0x4300 CFG0_MCU_MTOG0_CTRL access per field
  [31] MCU_MTOG0_CTRL_IDLE_STAT ro — Idle status When high, indicates MTOG0 is idle.
  [23:16] MCU_MTOG0_CTRL_FORCE_TIMEOUT rw — Force Timeout Forces a flush of the interface transactions. This bitfield is only relevant if timeout_en=1. After forcing a timeout by writing the encoded value, the force_timeout and timeout_en bitfields must be cleared to clear the timeout before re-enabling the gasket. 8'h95 - Force a gasket timeout All others - Normal operation
  [15] MCU_MTOG0_CTRL_TIMEOUT_EN rw — Timeout Enable 1'b0 - Disable the gasket. Clear the interrupt and reset the counter 1'b1 - Enable the timeout gasket functions
  [2:0] MCU_MTOG0_CTRL_TIMEOUT_VAL rw — Gasket Timeout Value Selects the number of clock cycles before the interface is considered to have timed out Field values (others are reserved): 3'b000 - 1024 clock cycles 3'b001 - 4096 clock cycles 3'b010 - 16,384 clock cycles 3'b011 - 65,536 clock cycles 3'b100 - 262,144 clock cycles 3'b101 - 1,048,576 clock cycles 3'b110 - 2,097,152 clock cycles 3'b111 - 4,194,303 clock cycles
{0x5100+4i} CFG0_CLAIMREG_P1_R{i}_READONLY ro (i=0..6)
  [31:0] CLAIMREG_P1_R{i}_READONLY — Claim bits for Partition 1
0x6030 CFG0_MSMC_CFG_PROXY access per field
  [11:8] MSMC_CFG_MEM_SIZE_PROXY ro — Indicates the size of MSMC shared SRAM/Cache Field values (others are reserved): undefined - undefined undefined - undefined undefined - undefined undefined - undefined undefined - undefined undefined - undefined undefined - undefined undefined - undefined undefined - undefined undefined - undefined undefined - undefined undefined - undefined undefined - undefined undefined - undefined 4'b0000 - 0.5 MB 4'b0001 - 1.75 MB 4'b0010 - 3.0 MB 4'b0011 - 4,25 MB 4'b0100 - 5.5 MB 4'b0101 - 6.75 MB 4'b0110 - 8 MB 4'b0111 - 9.25 MB 4'b1000 - 10.5 MB 4'b1001 - 11.75 MB 4'b1010 - 13.0 MB
  [4] MSMC_CFG_MEM_INIT_DIS_PROXY rw — Disables MSMC SRAM initialization (Data, Cache Tags, and Snoop Filters). This is required for proper initial ECC initialization. 1'b0 - Perform memory initialization 1'b1 - Disable memory initialization
0x6040 CFG0_MCU_ENET_CTRL_PROXY reset 0x1
  [4] MCU_ENET_CTRL_RGMII_ID_MODE_PROXY — Port1 RGMII internal transmit delay selection 0 - Internal transmit delay 1 - No internal transmit delay
  [1:0] MCU_ENET_CTRL_MODE_SEL_PROXY — Selects Ethernet switch Port1 interface Field values (others are reserved): 2'b00 - GMII/MII (not supported) 2'b01 - RMII 2'b10 - RGMII 2'b11 - SGMII (not supported)
